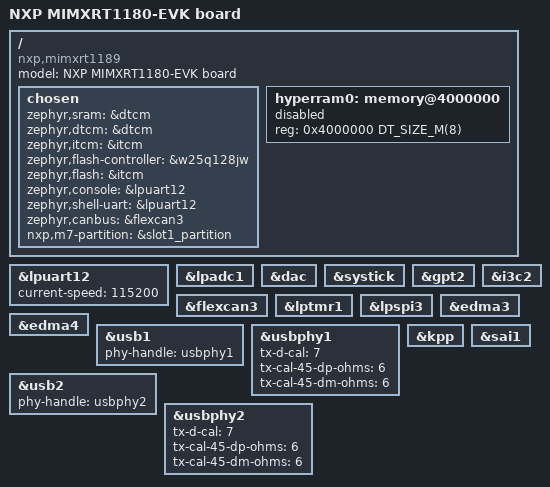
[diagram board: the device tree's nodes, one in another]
/*
 * Copyright 2024-2025 NXP
 *
 * SPDX-License-Identifier: Apache-2.0
 */

/dts-v1/;

#include <nxp/nxp_rt118x_cm7.dtsi>
#include "mimxrt1180_evk.dtsi"

/ {
	model = "NXP MIMXRT1180-EVK board";
	compatible = "nxp,mimxrt1189";

	chosen {
		zephyr,sram = &dtcm;
		zephyr,dtcm = &dtcm;
		zephyr,itcm = &itcm;
		zephyr,flash-controller = &w25q128jw;
		zephyr,flash = &itcm;
		zephyr,console = &lpuart12;
		zephyr,shell-uart = &lpuart12;
		zephyr,canbus = &flexcan3;
		nxp,m7-partition = &slot1_partition;
	};

	hyperram0: memory@4000000 {
		/* Winbond W957A8MFYA5K */
		device_type = "memory";
		reg = <0x4000000 DT_SIZE_M(8)>;
		/*
		 * Currently, HyperRAM on this board must be accessed under XIP mode,
		 * so that the ROM bootloader can initialize it by reading the XMCD configuration.
		 * These XMCD configurations are stored in the default settings file
		 * `xip/evkmimxrt1180_flexspi_nor_config.c`. (If modifications are needed,
		 * please refer to the examples and the "System Boot" chapter in the
		 * RT1180 Reference Manual.)
		 * The CM33 core of the MIMXRT1180_EVK runs in XIP mode and uses the
		 * HyperRAM space as the RAM region by default. Therefore, the status of the
		 * full hyperram0 memory node is set to "okay" for cm33 core.
		 * At this point, the CM7 core can also access the HyperRAM.
		 * However, since the entire HyperRAM region is occupied in the CM33's DTS,
		 * users can allocate the HyperRAM reasonably so that both cores (CM33 and CM7)
		 * can use HyperRAM as their RAM region.
		 *
		 * If not configured by the ROM bootloader, the user must ensure the hyperram0
		 * device is enabled in the DTS, otherwise, the user must set 'status = "disabled";
		 * Note: mpu_region.c uses the status property from the DTS to configure the
		 * corresponding MPU settings.
		 */
		status = "disabled";
	};
};

&lpuart12 {
	status = "okay";
	current-speed = <115200>;
};

&lpadc1 {
	status = "okay";
};

&dac {
	status = "okay";
};

&systick {
	status = "okay";
};

&gpt2 {
	status = "okay";
};

&flexcan3 {
	status = "okay";
};

&lptmr1 {
	status = "okay";
};

&i3c2 {
	status = "okay";
};

&lpspi3 {
	status = "okay";
};

&edma3 {
	status = "okay";
};

&edma4 {
	status = "okay";
};

zephyr_udc0: &usb1 {
	status = "okay";
	phy-handle = <&usbphy1>;
};

&usbphy1 {
	status = "okay";
	tx-d-cal = <7>;
	tx-cal-45-dp-ohms = <6>;
	tx-cal-45-dm-ohms = <6>;
};

zephyr_udc1: &usb2 {
	status = "okay";
	phy-handle = <&usbphy2>;
};

&usbphy2 {
	status = "okay";
	tx-d-cal = <7>;
	tx-cal-45-dp-ohms = <6>;
	tx-cal-45-dm-ohms = <6>;
};

&kpp {
	status = "okay";
};

&sai1 {
	status = "okay";
};
